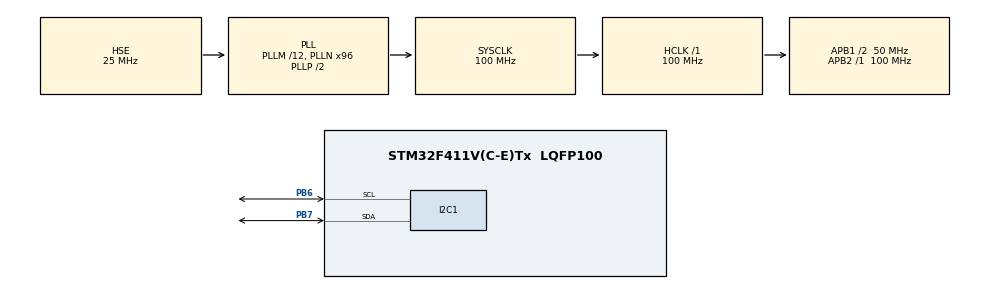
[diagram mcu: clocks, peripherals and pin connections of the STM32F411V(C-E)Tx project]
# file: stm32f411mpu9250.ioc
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Mcu.Family=STM32F4
RCC.PLLSourceVirtual=RCC_PLLSOURCE_HSE
RCC.CortexFreq_Value=100000000
PH1\ -\ OSC_OUT.Mode=HSE-External-Oscillator
RCC.APB1CLKDivider=RCC_HCLK_DIV2
RCC.SYSCLKSource=RCC_SYSCLKSOURCE_PLLCLK
ProjectManager.StackSize=0x400
PA13.Signal=SYS_JTMS-SWDIO
PH0\ -\ OSC_IN.Mode=HSE-External-Oscillator
PH0\ -\ OSC_IN.Signal=RCC_OSC_IN
ProjectManager.TargetToolchain=STM32CubeIDE
RCC.HCLKFreq_Value=100000000
RCC.APB2TimFreq_Value=100000000
PB6.Signal=I2C1_SCL
PB6.Mode=I2C
RCC.LSE_VALUE=32768
RCC.AHBFreq_Value=100000000
RCC.HSE_VALUE=25000000
PH1\ -\ OSC_OUT.Signal=RCC_OSC_OUT
board=custom
RCC.VCOOutputFreq_Value=200000000
RCC.APB2Freq_Value=100000000
PA14.Mode=Serial_Wire
PB7.Signal=I2C1_SDA
PA13.Mode=Serial_Wire
Mcu.Name=STM32F411V(C-E)Tx
RCC.48MHZClocksFreq_Value=50000000
RCC.SYSCLKFreq_VALUE=100000000
Mcu.Package=LQFP100
PB7.Mode=I2C
PA14.Signal=SYS_JTCK-SWCLK
ProjectManager.HeapSize=0x200
RCC.HSI_VALUE=16000000
NVIC.PriorityGroup=NVIC_PRIORITYGROUP_4
RCC.PLLM=12
RCC.PLLN=96
RCC.APB1TimFreq_Value=100000000
RCC.APB1Freq_Value=50000000

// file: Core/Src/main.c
/* USER CODE BEGIN Header */
/**
  ******************************************************************************
  * @file           : main.c
  * @brief          : Main program body
  ******************************************************************************
  * @attention
  *
  * <h2><center>&copy; Copyright (c) 2022 STMicroelectronics.
  * All rights reserved.</center></h2>
  *
  * This software component is licensed by ST under BSD 3-Clause license,
  * the "License"; You may not use this file except in compliance with the
  * License. You may obtain a copy of the License at:
  *                        opensource.org/licenses/BSD-3-Clause
  *
  ******************************************************************************
  */
/* USER CODE END Header */
#include "main.h"

/* USER CODE BEGIN Includes */
#include "mpu9250.h"

/* USER CODE END Includes */

I2C_HandleTypeDef hi2c1;

void SystemClock_Config(void);
static void MX_GPIO_Init(void);
static void MX_I2C1_Init(void);

int main(void)
{

  /* MCU Configuration--------------------------------------------------------*/

  /* Reset of all peripherals, Initializes the Flash interface and the Systick. */
  HAL_Init();

  /* Configure the system clock */
  SystemClock_Config();

  /* Initialize all configured peripherals */
  MX_GPIO_Init();
  MX_I2C1_Init();
  /* USER CODE BEGIN 2 */
  mpu9250Config();

  /* USER CODE END 2 */

  /* Infinite loop */
  while (1)
  {
	  	  mpu9250GyroRead();
	 	  mpu9250AccelRead();
	 	  HAL_Delay(200);

  }
}

void SystemClock_Config(void)
{
  RCC_OscInitTypeDef RCC_OscInitStruct = {0};
  RCC_ClkInitTypeDef RCC_ClkInitStruct = {0};

  /** Configure the main internal regulator output voltage
  */
  __HAL_RCC_PWR_CLK_ENABLE();
  __HAL_PWR_VOLTAGESCALING_CONFIG(PWR_REGULATOR_VOLTAGE_SCALE1);
  /** Initializes the RCC Oscillators according to the specified parameters
  * in the RCC_OscInitTypeDef structure.
  */
  RCC_OscInitStruct.OscillatorType = RCC_OSCILLATORTYPE_HSE;
  RCC_OscInitStruct.HSEState = RCC_HSE_ON;
  RCC_OscInitStruct.PLL.PLLState = RCC_PLL_ON;
  RCC_OscInitStruct.PLL.PLLSource = RCC_PLLSOURCE_HSE;
  RCC_OscInitStruct.PLL.PLLM = 12;
  RCC_OscInitStruct.PLL.PLLN = 96;
  RCC_OscInitStruct.PLL.PLLP = RCC_PLLP_DIV2;
  RCC_OscInitStruct.PLL.PLLQ = 4;
  if (HAL_RCC_OscConfig(&RCC_OscInitStruct) != HAL_OK)
  {
    Error_Handler();
  }
  /** Initializes the CPU, AHB and APB buses clocks
  */
  RCC_ClkInitStruct.ClockType = RCC_CLOCKTYPE_HCLK|RCC_CLOCKTYPE_SYSCLK
                              |RCC_CLOCKTYPE_PCLK1|RCC_CLOCKTYPE_PCLK2;
  RCC_ClkInitStruct.SYSCLKSource = RCC_SYSCLKSOURCE_PLLCLK;
  RCC_ClkInitStruct.AHBCLKDivider = RCC_SYSCLK_DIV1;
  RCC_ClkInitStruct.APB1CLKDivider = RCC_HCLK_DIV2;
  RCC_ClkInitStruct.APB2CLKDivider = RCC_HCLK_DIV1;

  if (HAL_RCC_ClockConfig(&RCC_ClkInitStruct, FLASH_LATENCY_3) != HAL_OK)
  {
    Error_Handler();
  }
}

static void MX_I2C1_Init(void)
{

  hi2c1.Instance = I2C1;
  hi2c1.Init.ClockSpeed = 100000;
  hi2c1.Init.DutyCycle = I2C_DUTYCYCLE_2;
  hi2c1.Init.OwnAddress1 = 0;
  hi2c1.Init.AddressingMode = I2C_ADDRESSINGMODE_7BIT;
  hi2c1.Init.DualAddressMode = I2C_DUALADDRESS_DISABLE;
  hi2c1.Init.OwnAddress2 = 0;
  hi2c1.Init.GeneralCallMode = I2C_GENERALCALL_DISABLE;
  hi2c1.Init.NoStretchMode = I2C_NOSTRETCH_DISABLE;
  if (HAL_I2C_Init(&hi2c1) != HAL_OK)
  {
    Error_Handler();
  }

}

static void MX_GPIO_Init(void)
{

  /* GPIO Ports Clock Enable */
  __HAL_RCC_GPIOH_CLK_ENABLE();
  __HAL_RCC_GPIOA_CLK_ENABLE();
  __HAL_RCC_GPIOB_CLK_ENABLE();

}

void Error_Handler(void)
{
  __disable_irq();
  while (1)
  {
  }
}

/************************ (C) COPYRIGHT STMicroelectronics *****END OF FILE****/
